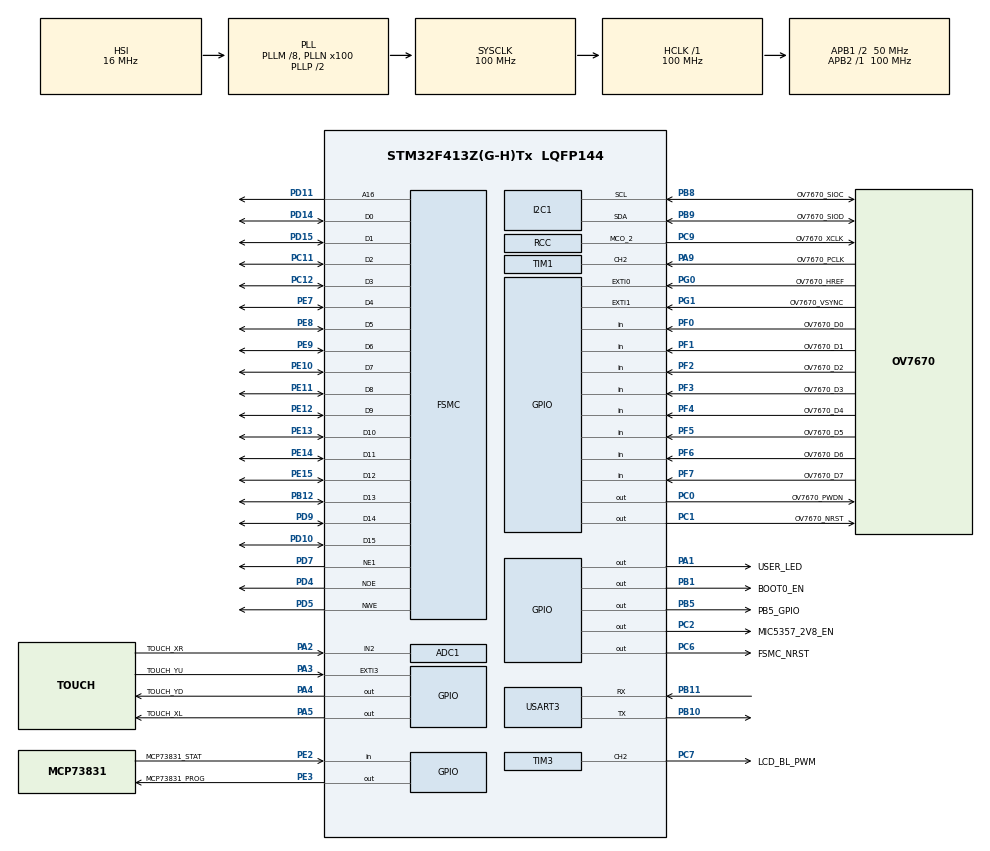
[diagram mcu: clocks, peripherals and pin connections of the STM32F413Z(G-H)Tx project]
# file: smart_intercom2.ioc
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ADC1.Channel-0\#ChannelRegularConversion=ADC_CHANNEL_2
ADC1.Channel-1\#ChannelRegularConversion=ADC_CHANNEL_2
ADC1.NbrOfConversion=2
ADC1.NbrOfConversionFlag=1
ADC1.Rank-0\#ChannelRegularConversion=1
ADC1.Rank-1\#ChannelRegularConversion=2
ADC1.SamplingTime-0\#ChannelRegularConversion=ADC_SAMPLETIME_3CYCLES
ADC1.SamplingTime-1\#ChannelRegularConversion=ADC_SAMPLETIME_3CYCLES
ADC1.master=1
Dma.Request0=TIM1_TRIG
Dma.TIM1_TRIG.0.Direction=DMA_PERIPH_TO_MEMORY
Dma.TIM1_TRIG.0.FIFOMode=DMA_FIFOMODE_DISABLE
Dma.TIM1_TRIG.0.Instance=DMA2_Stream0
Dma.TIM1_TRIG.0.MemDataAlignment=DMA_MDATAALIGN_BYTE
Dma.TIM1_TRIG.0.MemInc=DMA_MINC_ENABLE
Dma.TIM1_TRIG.0.Mode=DMA_NORMAL
Dma.TIM1_TRIG.0.PeriphDataAlignment=DMA_PDATAALIGN_BYTE
Dma.TIM1_TRIG.0.PeriphInc=DMA_PINC_DISABLE
Dma.TIM1_TRIG.0.Priority=DMA_PRIORITY_HIGH
FSMC.AddressSetupTime1=9
FSMC.BusTurnAroundDuration1=1
FSMC.DataSetupTime1=5
FSMC.ExtendedAddressSetupTime1=2
FSMC.ExtendedBusTurnAroundDuration1=1
FSMC.ExtendedDataSetupTime1=3
FSMC.ExtendedMode1=FSMC_EXTENDED_MODE_ENABLE
I2C1.I2C_Mode=I2C_Fast
I2C1.NoStretchMode=I2C_NOSTRETCH_ENABLE
I2C1.OwnAddress=0x21
Mcu.Family=STM32F4
Mcu.Name=STM32F413Z(G-H)Tx
Mcu.Package=LQFP144
NVIC.EXTI0_IRQn=true\:0\:0\:false\:false\:true\:true\:true
NVIC.EXTI1_IRQn=true\:1\:0\:true\:false\:true\:true\:true
NVIC.EXTI3_IRQn=true\:0\:0\:false\:false\:true\:true\:true
NVIC.I2C1_EV_IRQn=true\:0\:0\:false\:false\:true\:true\:true
NVIC.PriorityGroup=NVIC_PRIORITYGROUP_4
NVIC.USART3_IRQn=true\:0\:0\:false\:false\:true\:true\:true
PA1.GPIO_Label=USER_LED
PA1.Signal=GPIO_Output
PA13.Mode=Trace_Asynchronous_SW
PA13.Signal=SYS_JTMS-SWDIO
PA14.Mode=Trace_Asynchronous_SW
PA14.Signal=SYS_JTCK-SWCLK
PA2.GPIO_Label=TOUCH_XR
PA2.Signal=ADCx_IN2
PA3.GPIO_Label=TOUCH_YU
PA3.GPIO_ModeDefaultEXTI=GPIO_MODE_IT_FALLING
PA3.GPIO_PuPd=GPIO_PULLUP
PA3.Signal=GPXTI3
PA4.GPIO_Label=TOUCH_YD
PA4.Signal=GPIO_Output
PA5.GPIO_Label=TOUCH_XL
PA5.Signal=GPIO_Output
PA9.GPIO_Label=OV7670_PCLK
PA9.GPIO_PuPd=GPIO_NOPULL
PA9.Signal=S_TIM1_CH2
PB1.GPIO_Label=BOOT0_EN
PB1.GPIO_ModeDefaultOutputPP=GPIO_MODE_OUTPUT_PP
PB1.GPIO_PuPd=GPIO_NOPULL
PB1.Signal=GPIO_Output
PB10.Mode=Asynchronous
PB10.Signal=USART3_TX
PB11.Mode=Asynchronous
PB11.Signal=USART3_RX
PB12.Signal=FSMC_D13_DA13
PB3.Mode=Trace_Asynchronous_SW
PB3.Signal=SYS_JTDO-SWO
PB5.GPIO_Label=PB5_GPIO
PB5.GPIO_ModeDefaultOutputPP=GPIO_MODE_OUTPUT_OD
PB5.GPIO_PuPd=GPIO_NOPULL
PB5.Signal=GPIO_Output
PB8.GPIO_Label=OV7670_SIOC
PB8.Mode=I2C
PB8.Signal=I2C1_SCL
PB9.GPIO_Label=OV7670_SIOD
PB9.Mode=I2C
PB9.Signal=I2C1_SDA
PC0.GPIO_Label=OV7670_PWDN
PC0.GPIO_ModeDefaultOutputPP=GPIO_MODE_OUTPUT_PP
PC0.GPIO_PuPd=GPIO_NOPULL
PC0.Signal=GPIO_Output
PC1.GPIO_Label=OV7670_NRST
PC1.GPIO_ModeDefaultOutputPP=GPIO_MODE_OUTPUT_OD
PC1.GPIO_PuPd=GPIO_NOPULL
PC1.PinState=GPIO_PIN_RESET
PC1.Signal=GPIO_Output
PC11.Signal=FSMC_D2_DA2
PC12.Signal=FSMC_D3_DA3
PC2.GPIO_Label=MIC5357_2V8_EN
PC2.Signal=GPIO_Output
PC6.GPIO_Label=FSMC_NRST
PC6.Signal=GPIO_Output
PC7.GPIO_Label=LCD_BL_PWM
PC7.GPIO_ModeDefaultPP=GPIO_MODE_AF_OD
PC7.Signal=S_TIM3_CH2
PC9.GPIO_Label=OV7670_XCLK
PC9.GPIO_Speed=GPIO_SPEED_FREQ_VERY_HIGH
PC9.Mode=Clock-out-2
PC9.Signal=RCC_MCO_2
PD10.Signal=FSMC_D15_DA15
PD11.Signal=FSMC_A16
PD14.Signal=FSMC_D0_DA0
PD15.Signal=FSMC_D1_DA1
PD4.Signal=FSMC_NOE
PD5.Signal=FSMC_NWE
PD7.Mode=NorPsramChipSelect1_1
PD7.Signal=FSMC_NE1
PD9.Signal=FSMC_D14_DA14
PE10.Signal=FSMC_D7_DA7
PE11.Signal=FSMC_D8_DA8
PE12.Signal=FSMC_D9_DA9
PE13.Signal=FSMC_D10_DA10
PE14.Signal=FSMC_D11_DA11
PE15.Signal=FSMC_D12_DA12
PE2.GPIO_Label=MCP73831_STAT
PE2.Signal=GPIO_Input
PE3.GPIO_Label=MCP73831_PROG
PE3.GPIO_ModeDefaultOutputPP=GPIO_MODE_OUTPUT_OD
PE3.GPIO_PuPd=GPIO_NOPULL
PE3.PinState=GPIO_PIN_SET
PE3.Signal=GPIO_Output
PE7.Signal=FSMC_D4_DA4
PE8.Signal=FSMC_D5_DA5
PE9.Signal=FSMC_D6_DA6
PF0.GPIO_Label=OV7670_D0
PF0.Signal=GPIO_Input
PF1.GPIO_Label=OV7670_D1
PF1.Signal=GPIO_Input
PF2.GPIO_Label=OV7670_D2
PF2.Signal=GPIO_Input
PF3.GPIO_Label=OV7670_D3
PF3.Signal=GPIO_Input
PF4.GPIO_Label=OV7670_D4
PF4.Signal=GPIO_Input
PF5.GPIO_Label=OV7670_D5
PF5.Signal=GPIO_Input
PF6.GPIO_Label=OV7670_D6
PF6.Signal=GPIO_Input
PF7.GPIO_Label=OV7670_D7
PF7.Signal=GPIO_Input
PG0.GPIO_Label=OV7670_HREF
PG0.GPIO_ModeDefaultEXTI=GPIO_MODE_IT_FALLING
PG0.Signal=GPXTI0
PG1.GPIO_Label=OV7670_VSYNC
PG1.GPIO_ModeDefaultEXTI=GPIO_MODE_IT_RISING_FALLING
PG1.Signal=GPXTI1
ProjectManager.HeapSize=0x200
ProjectManager.StackSize=0x400
ProjectManager.TargetToolchain=STM32CubeIDE
RCC.AHBFreq_Value=100000000
RCC.APB1CLKDivider=RCC_HCLK_DIV2
RCC.APB1Freq_Value=50000000
RCC.APB1TimFreq_Value=100000000
RCC.APB2Freq_Value=100000000
RCC.APB2TimFreq_Value=100000000
RCC.CortexFreq_Value=100000000
RCC.HCLKFreq_Value=100000000
RCC.PLLM=8
RCC.PLLN=100
RCC.RCC_TIM_PRescaler_Selection=RCC_TIMPRES_ACTIVATED
RCC.SYSCLKFreq_VALUE=100000000
RCC.SYSCLKSource=RCC_SYSCLKSOURCE_PLLCLK
RCC.USBFreq_Value=100000000
RCC.VCOOutputFreq_Value=200000000
SH.ADCx_IN2.0=ADC1_IN2,IN2
SH.FSMC_A16.0=FSMC_A16,A16_1
SH.FSMC_D0_DA0.0=FSMC_D0,16b-d1
SH.FSMC_D10_DA10.0=FSMC_D10,16b-d1
SH.FSMC_D11_DA11.0=FSMC_D11,16b-d1
SH.FSMC_D12_DA12.0=FSMC_D12,16b-d1
SH.FSMC_D13_DA13.0=FSMC_D13,16b-d1
SH.FSMC_D14_DA14.0=FSMC_D14,16b-d1
SH.FSMC_D15_DA15.0=FSMC_D15,16b-d1
SH.FSMC_D1_DA1.0=FSMC_D1,16b-d1
SH.FSMC_D2_DA2.0=FSMC_D2,16b-d1
SH.FSMC_D3_DA3.0=FSMC_D3,16b-d1
SH.FSMC_D4_DA4.0=FSMC_D4,16b-d1
SH.FSMC_D5_DA5.0=FSMC_D5,16b-d1
SH.FSMC_D6_DA6.0=FSMC_D6,16b-d1
SH.FSMC_D7_DA7.0=FSMC_D7,16b-d1
SH.FSMC_D8_DA8.0=FSMC_D8,16b-d1
SH.FSMC_D9_DA9.0=FSMC_D9,16b-d1
SH.FSMC_NOE.0=FSMC_NOE,Lcd1
SH.FSMC_NWE.0=FSMC_NWE,Lcd1
SH.S_TIM1_CH2.0=TIM1_CH2,TriggerSource_TI2FP2
SH.S_TIM3_CH2.0=TIM3_CH2,PWM Generation2 CH2
TIM3.Channel-PWM\ Generation2\ CH2=TIM_CHANNEL_2
TIM3.Pulse-PWM\ Generation2\ CH2=32000
USART3.VirtualMode=VM_ASYNC
VP_TIM1_VS_ControllerModeClock.Mode=Clock Mode
board=custom

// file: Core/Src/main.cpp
/* USER CODE BEGIN Header */
/**
  ******************************************************************************
  * @file           : main.c
  * @brief          : Main program body
  ******************************************************************************
  * @attention
  *
  * <h2><center>&copy; Copyright (c) 2021 STMicroelectronics.
  * All rights reserved.</center></h2>
  *
  * This software component is licensed by ST under BSD 3-Clause license,
  * the "License"; You may not use this file except in compliance with the
  * License. You may obtain a copy of the License at:
  *                        opensource.org/licenses/BSD-3-Clause
  *
  ******************************************************************************
  */
/* USER CODE END Header */
#include "main.h"
#include "adc.h"
#include "dma.h"
#include "i2c.h"
#include "tim.h"
#include "usart.h"
#include "gpio.h"
#include "fsmc.h"

/* USER CODE BEGIN Includes */
#include "../Inc/app_main.h"
#include "tensorflow/lite/micro/examples/person_detection/main_functions.h"

/* USER CODE END Includes */

void SystemClock_Config(void);

int main(void)
{

  /* MCU Configuration--------------------------------------------------------*/

  /* Reset of all peripherals, Initializes the Flash interface and the Systick. */
  HAL_Init();

  /* Configure the system clock */
  SystemClock_Config();

  /* Initialize all configured peripherals */
  MX_GPIO_Init();
  MX_DMA_Init();
  MX_TIM1_Init();
  MX_FSMC_Init();
  MX_I2C1_Init();
  MX_TIM3_Init();
  MX_USART3_UART_Init();
  MX_ADC1_Init();
  /* USER CODE BEGIN 2 */
  app_main_init();
  /* USER CODE END 2 */

  /* Infinite loop */
  /* USER CODE BEGIN WHILE */
  while (1)
  {
	  app_main_loop();
    /* USER CODE END WHILE */

  }
}

void SystemClock_Config(void)
{
  RCC_OscInitTypeDef RCC_OscInitStruct = {0};
  RCC_ClkInitTypeDef RCC_ClkInitStruct = {0};
  RCC_PeriphCLKInitTypeDef PeriphClkInitStruct = {0};

  /** Configure the main internal regulator output voltage
  */
  __HAL_RCC_PWR_CLK_ENABLE();
  __HAL_PWR_VOLTAGESCALING_CONFIG(PWR_REGULATOR_VOLTAGE_SCALE1);
  /** Initializes the RCC Oscillators according to the specified parameters
  * in the RCC_OscInitTypeDef structure.
  */
  RCC_OscInitStruct.OscillatorType = RCC_OSCILLATORTYPE_HSI;
  RCC_OscInitStruct.HSIState = RCC_HSI_ON;
  RCC_OscInitStruct.HSICalibrationValue = RCC_HSICALIBRATION_DEFAULT;
  RCC_OscInitStruct.PLL.PLLState = RCC_PLL_ON;
  RCC_OscInitStruct.PLL.PLLSource = RCC_PLLSOURCE_HSI;
  RCC_OscInitStruct.PLL.PLLM = 8;
  RCC_OscInitStruct.PLL.PLLN = 100;
  RCC_OscInitStruct.PLL.PLLP = RCC_PLLP_DIV2;
  RCC_OscInitStruct.PLL.PLLQ = 2;
  RCC_OscInitStruct.PLL.PLLR = 2;
  if (HAL_RCC_OscConfig(&RCC_OscInitStruct) != HAL_OK)
  {
    Error_Handler();
  }
  /** Initializes the CPU, AHB and APB buses clocks
  */
  RCC_ClkInitStruct.ClockType = RCC_CLOCKTYPE_HCLK|RCC_CLOCKTYPE_SYSCLK
                              |RCC_CLOCKTYPE_PCLK1|RCC_CLOCKTYPE_PCLK2;
  RCC_ClkInitStruct.SYSCLKSource = RCC_SYSCLKSOURCE_PLLCLK;
  RCC_ClkInitStruct.AHBCLKDivider = RCC_SYSCLK_DIV1;
  RCC_ClkInitStruct.APB1CLKDivider = RCC_HCLK_DIV2;
  RCC_ClkInitStruct.APB2CLKDivider = RCC_HCLK_DIV1;

  if (HAL_RCC_ClockConfig(&RCC_ClkInitStruct, FLASH_LATENCY_3) != HAL_OK)
  {
    Error_Handler();
  }
  PeriphClkInitStruct.PeriphClockSelection = RCC_PERIPHCLK_TIM;
  PeriphClkInitStruct.TIMPresSelection = RCC_TIMPRES_ACTIVATED;
  if (HAL_RCCEx_PeriphCLKConfig(&PeriphClkInitStruct) != HAL_OK)
  {
    Error_Handler();
  }
  HAL_RCC_MCOConfig(RCC_MCO2, RCC_MCO2SOURCE_SYSCLK, RCC_MCODIV_5);
}

void Error_Handler(void)
{
  __disable_irq();
  while (1)
  {
  }
}

/************************ (C) COPYRIGHT STMicroelectronics *****END OF FILE****/
